# AT91SAM9CN12 register map
Vendor: Atmel; Series: SAM9CN; File version: 20130208
Registers are 32-bit, read-only, reset 0x0 unless marked. A register's access mark holds for its fields unless they carry their own. Offsets are from the block's base; [hi:lo] are bit positions; {n}, {i} and the like mark numbered series.

## PMERRLOC — Programmable Multibit ECC Error Location
Base 0xFFFFE600; register names take the prefix PMERRLOC_
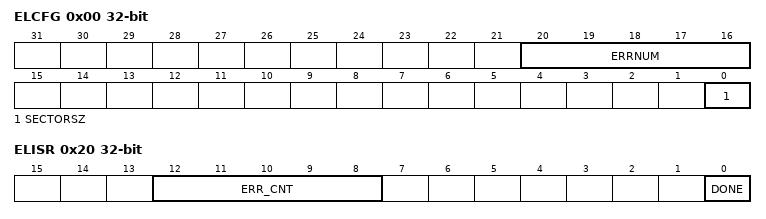
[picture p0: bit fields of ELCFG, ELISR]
0x00 ELCFG rw — Error Location Configuration Register
  [20:16] ERRNUM — Number of Errors
  [0] SECTORSZ — Sector Size
0x04 ELPRIM — Error Location Primitive Register
  [15:0] PRIMITIV — Primitive Polynomial
0x08 ELEN rw — Error Location Enable Register
  [13:0] ENINIT — Initial Number of Bits in the Codeword
0x0C ELDIS rw — Error Location Disable Register
  [0] DIS — Disable Error Location Engine
0x10 ELSR rw — Error Location Status Register
  [0] BUSY — Error Location Engine Busy
0x14 ELIER — Error Location Interrupt Enable register
  [0] DONE — Computation Terminated Interrupt Enable
0x18 ELIDR — Error Location Interrupt Disable Register
  [0] DONE — Computation Terminated Interrupt Disable
0x1C ELIMR — Error Location Interrupt Mask Register
  [0] DONE — Computation Terminated Interrupt Mask
0x20 ELISR — Error Location Interrupt Status Register
  [12:8] ERR_CNT — Error Counter value
  [0] DONE — Computation Terminated Interrupt Status
{0x28+4i} SIGMA[{i}] (i=0..24) rw reset not defined — PMECC SIGMA 0 Register
  [13:0] SIGMAN
{0x8C+4i} EL[{i}] (i=0..23) reset not defined — PMECC Error Location 0 Register
  [13:0] ERRLOCN — Error Position within the set {sector area, spare area}.

## DDRSDRC — DDR_SDR SDRAM Controller
Base 0xFFFFE800; register names take the prefix DDRSDRC_
0x00 MR rw — DDRSDRC Mode Register
  [2:0] MODE — DDRSDRC Command Mode
0x04 RTR rw — DDRSDRC Refresh Timer Register
  [11:0] COUNT — DDRSDRC Refresh Timer Count
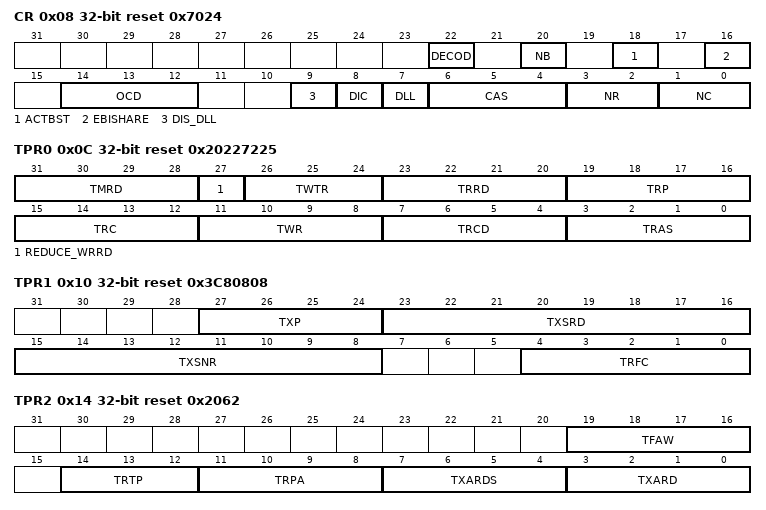
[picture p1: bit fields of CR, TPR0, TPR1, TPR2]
0x08 CR rw reset 0x7024 — DDRSDRC Configuration Register
  [22] DECOD — Type of Decoding
  [20] NB — Number of Banks
  [18] ACTBST — ACTIVE Bank X to Burst Stop Read Access Bank Y
  [16] EBISHARE — External Bus Interface is Shared
  [14:12] OCD — Off-chip Driver
  [9] DIS_DLL — Disable DLL
  [8] DIC — Output Driver Impedance Control
  [7] DLL — Reset DLL
  [6:4] CAS — CAS Latency
  [3:2] NR — Number of Row Bits
  [1:0] NC — Number of Column Bits
0x0C TPR0 rw reset 0x20227225 — DDRSDRC Timing Parameter 0 Register
  [31:28] TMRD — Load Mode Register Command to Active or Refresh Command
  [27] REDUCE_WRRD — Reduce Write to Read Delay
  [26:24] TWTR — Internal Write to Read Delay
  [23:20] TRRD — Active bankA to Active bankB
  [19:16] TRP — Row Precharge Delay
  [15:12] TRC — Row Cycle Delay
  [11:8] TWR — Write Recovery Delay
  [7:4] TRCD — Row to Column Delay
  [3:0] TRAS — Active to Precharge Delay
0x10 TPR1 rw reset 0x3C80808 — DDRSDRC Timing Parameter 1 Register
  [27:24] TXP — Exit Power-down Delay to First Command
  [23:16] TXSRD — ExiT Self Refresh Delay to Read Command
  [15:8] TXSNR — Exit Self Refresh Delay to Non-read Command
  [4:0] TRFC — Row Cycle Delay
0x14 TPR2 rw reset 0x2062 — DDRSDRC Timing Parameter 2 Register
  [19:16] TFAW — Four Active window
  [14:12] TRTP — Read to Precharge
  [11:8] TRPA — Row Precharge All Delay
  [7:4] TXARDS — Exit Active Power Down Delay to Read Command in Mode "Slow Exit".
  [3:0] TXARD — Exit Active Power Down Delay to Read Command in Mode "Fast Exit".
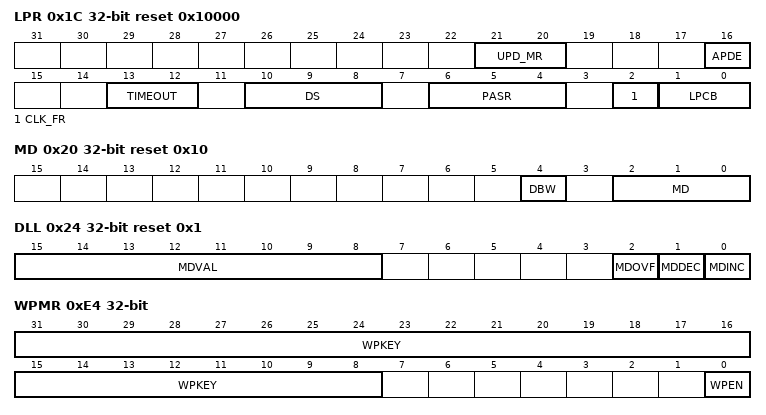
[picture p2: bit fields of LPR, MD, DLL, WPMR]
0x1C LPR rw reset 0x10000 — DDRSDRC Low-power Register
  [21:20] UPD_MR — Update Load Mode Register and Extended Mode Register
  [16] APDE — Active Power Down Exit Time
  [13:12] TIMEOUT — Low Power Mode
  [10:8] DS — Drive Strength
  [6:4] PASR — Partial Array Self Refresh
  [2] CLK_FR — Clock Frozen Command Bit
  [1:0] LPCB — Low-power Command Bit
0x20 MD rw reset 0x10 — DDRSDRC Memory Device Register
  [4] DBW — Data Bus Width
  [2:0] MD — Memory Device
0x24 DLL reset 0x1 — DDRSDRC DLL Information Register
  [15:8] MDVAL — DLL Master Delay Value
  [2] MDOVF — DLL Master Delay Overflow Flag
  [1] MDDEC — DLL Master Delay Decrement
  [0] MDINC — DLL Master Delay Increment
0x2C HS rw — DDRSDRC High Speed Register
  [2] DIS_ANTICIP_READ — Anticip Read Access
0xE4 WPMR rw — DDRSDRC Write Protect Mode Register
  [31:8] WPKEY — Write Protect KEY
  [0] WPEN — Write Protect Enable
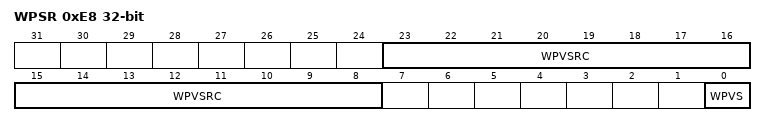
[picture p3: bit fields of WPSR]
0xE8 WPSR — DDRSDRC Write Protect Status Register
  [23:8] WPVSRC — Write Protect Violation Source
  [0] WPVS — Write Protect Violation Status
